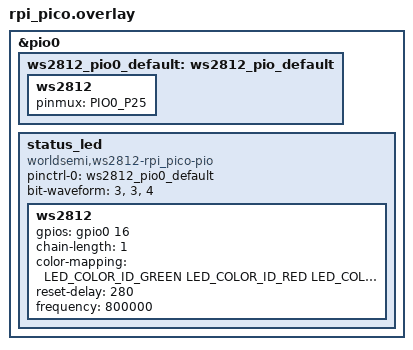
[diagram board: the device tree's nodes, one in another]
#include <zephyr/dt-bindings/pinctrl/rpi-pico-rp2040-pinctrl.h>
#include <dt-bindings/led/led.h>
#include <rpi_pico/rp2040.dtsi>
// #include "boards/sparkfun/pro_micro_rp2040/sparkfun_pro_micro_rp2040-pinctrl.dtsi"
// #include "sparkfun_pro_micro_rp2040-pinctrl.dtsi"
// #include "sparkfun_pro_micro_connector.dtsi"
// #include <zephyr/boards/adafruit/kb2040/adafruit_kb2040-pinctrl.dtsi>
#include <freq.h>

// &pio0 means that this overlay is a child of pio0, which should be defined for the rp2040 board already
&pio0 {
	status = "okay";
	// Defined in zephyrproject/zephyr/drivers/led_strip/ws2812_rpi_pico_pio.c
	// Does this need a 'compatible'?
	ws2812_pio0_default: ws2812_pio_default {
		ws2812 {
			pinmux = <PIO0_P25>;
		};
	};

	// Label and a unique name. Both match here.
	// A name with an `@<address>` implies a `reg` property
	status_led: status_led {
		// From zephyrproject/zephyr/dts/bindings/led_strip/worldsemi,ws2812-rpi_pico-pio.yaml
		// This is what gives it its name. It has its own `compatible` key which matches.
		compatible = "worldsemi,ws2812-rpi_pico-pio";
		// Why are these needed?
		status = "okay";
		// From pinctrl-device.yaml
		pinctrl-0 = <&ws2812_pio0_default>;
		// Needs to match number of pinctrl defined
		pinctrl-names = "default";
		// The property below are defined in the yaml
		// Fraction of time in each state. Compare to my Zig driver?
		// Seems to be 2, 5, 2O
		bit-waveform = <3>, <3>, <4>;

		// From ws2812.yaml, which was included in ws2812-gpio.yaml,
		// which was included in worldsemi,ws2812-rpi_pico-pio.yaml
		ws2812: ws2812 {
			status = "okay";
			// From ws2812-gpio.yaml
			gpios = <&gpio0 16 GPIO_ACTIVE_HIGH>;
			// From led-strip.yaml
			chain-length = <1>;
			// From led-strip.yaml
			color-mapping = <LED_COLOR_ID_GREEN
				LED_COLOR_ID_RED
				LED_COLOR_ID_BLUE>;
			// From ws2812.yaml
			reset-delay = <280>;
			// From worldsemi,...
			frequency = <800000>;
		};
	};
};
